# GD32H77x_78x register map
File version: 1.0
CPU: CM7 r1p2, little endian, MPU, FPU, 4 interrupt priority bits
Registers are 32-bit, read-write, reset 0x0 unless marked. A register's access mark holds for its fields unless they carry their own. Offsets are from the block's base; [hi:lo] are bit positions; {n}, {i} and the like mark numbered series.

## RSPDIF — Receiver of Sony/Philips Digtial Interface
Base 0x40004000
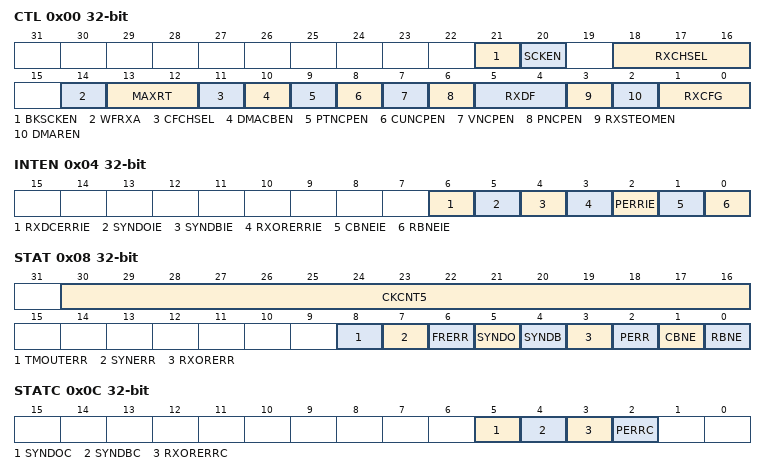
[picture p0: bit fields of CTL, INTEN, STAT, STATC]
0x00 CTL — Control register
  [21] BKSCKEN — Backup symbol clock enable
  [20] SCKEN — Symbol clock enable
  [18:16] RXCHSEL — RSPDIF input channel selection
  [14] WFRXA — Wait for the four valid transition signal of the selected RSPDIF channel
  [13:12] MAXRT — Maximum number of retries allowed during the RSPDIF synchronization phase 00: Do not allow retry (only one chance)
  [11] CFCHSEL — The control flow acquires channel state source selection
  [10] DMACBEN — Control buffer DMA enable for control flow
  [9] PTNCPEN — Preamble type no copy enable bit
  [8] CUNCPEN — Channel status and user no copy enable bit
  [7] VNCPEN — Validity no copy enable bit
  [6] PNCPEN — Parity error no copy enable bit
  [5:4] RXDF — RX data format selection
  [3] RXSTEOMEN — RX stereo mode enable
  [2] DMAREN — Receiver DMA enable for data flow
  [1:0] RXCFG — RSPDIF configuration
0x04 INTEN — Interrupt enable register
  [6] RXDCERRIE — RSPDIF data decoding error interrupt enable
  [5] SYNDOIE — Synchronization done interrupt enable
  [4] SYNDBIE — Synchronization block detected interrupt enable
  [3] RXORERRIE — RX overrun error interrupt enable
  [2] PERRIE — Parity error interrupt enable
  [1] CBNEIE — RX control buffer is no empty interrupt enable
  [0] RBNEIE — RX buffer is no empty interrupt enable
0x08 STAT ro — Status register
  [30:16] CKCNT5 — The number of consecutive time clock cycles of 5 symbols counted using ck
  [8] TMOUTERR — Time out error
  [7] SYNERR — Synchronization error
  [6] FRERR — Frame error
  [5] SYNDO — Synchronization done
  [4] SYNDB — Synchronization block detected
  [3] RXORERR — RX overrun error
  [2] PERR — Parity error
  [1] CBNE — The control buffer register is not empty
  [0] RBNE — RX data register not empty
0x0C STATC wo — Status flag clear register
  [5] SYNDOC — clears the synchronization done flag
  [4] SYNDBC — clears the synchronization block detected flag
  [3] RXORERRC — clears the RX overrun error flag
  [2] PERRC — clears the parity error flag
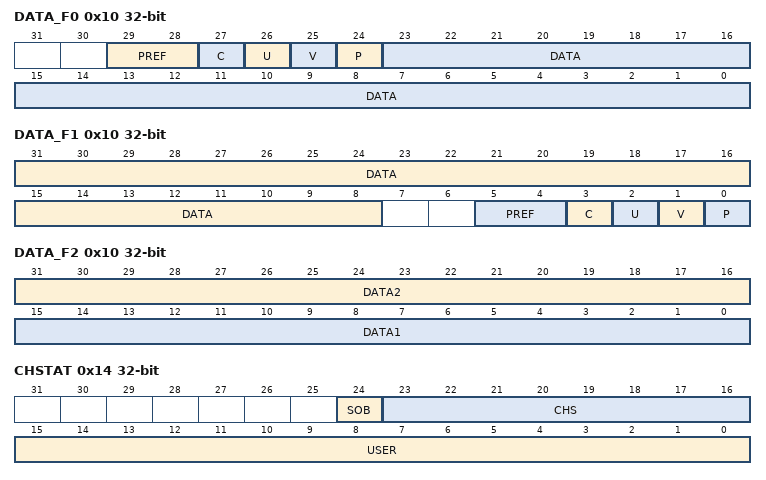
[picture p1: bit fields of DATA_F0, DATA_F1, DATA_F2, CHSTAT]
0x10 DATA_F0 ro — RX data register format 0
  [29:28] PREF — Preamble type
  [27] C — Channel status bit
  [26] U — User bit
  [25] V — Validity bit
  [24] P — Parity error bit
  [23:0] DATA — Data value
0x10 DATA_F1 ro (alternate view of DATA_F0) — RX data register format 1
  [31:8] DATA — Data value
  [5:4] PREF — Preamble type
  [3] C — Channel status bit
  [2] U — User bit
  [1] V — Validity bit
  [0] P — Parity error bit
0x10 DATA_F2 ro (alternate view of DATA_F0) — RX data register format 2
  [31:16] DATA2 — Data value
  [15:0] DATA1 — Data value
0x14 CHSTAT ro — RX Channel status register
  [24] SOB — Start of block
  [23:16] CHS — Channel A status information
  [15:0] USER — User data information
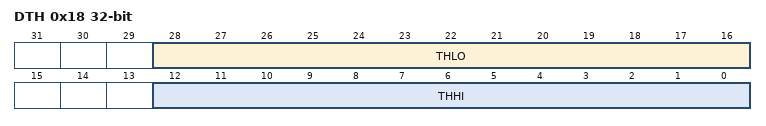
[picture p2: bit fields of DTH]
0x18 DTH ro — RX data threshold register
  [28:16] THLO — Low threshold
  [12:0] THHI — High threshold

## RTDEC0 — Real-time decryption
Base 0x5200B800
Same registers: RTDEC1 0x5200BC00
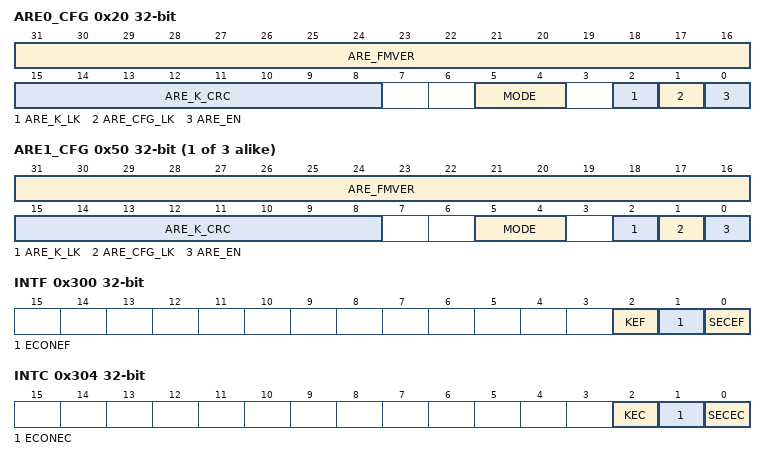
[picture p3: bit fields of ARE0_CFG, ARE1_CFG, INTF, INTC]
0x20 ARE0_CFG access per field — Area 0 configuration regist
  [31:16] ARE_FMVER rw — Area firmware version bits
  [15:8] ARE_K_CRC ro — 8-bit CRC of area key bits
  [5:4] MODE rw — RTDEC mode bits
  [2] ARE_K_LK ro — Area key lock bit
  [1] ARE_CFG_LK ro — Area configure lock bit
  [0] ARE_EN rw — Area real-time decryption enable bit
{0x24+0x30*i} ARE{i}_SADDR (i=0..3) — Area {i} start address regist
  [31:0] ARE_SADDR — Area x start address bits
{0x28+0x30*i} ARE{i}_EADDR reset 0xFFFF (i=0..3) — Area {i} end address regist
  [31:0] ARE_EADDR — Area x end address bits
0x2C ARE0_NONCE0 — Area 0 nonce 0 register 0
  [31:0] ARE_NONCE0 — Area 0 nonce address bits
0x30 ARE0_NONCE1 — Area 0 nonce register 1
  [31:0] ARE_NONCE1 — Area 0 nonce 1 address bits
{0x34+0x30*i} ARE{i}_KEY0 wo (i=0..3) — Area {i} key register
  [31:0] ARE_KEY0 — Area x key bits, ARE_KEY[31:0]
{0x38+0x30*i} ARE{i}_KEY1 wo (i=0..3) — Area {i} key register
  [31:0] ARE_KEY1 — Area x key bits, ARE_KEY[63:32]
{0x3C+0x30*i} ARE{i}_KEY2 wo (i=0..3) — Area {i} key register
  [31:0] ARE_KEY2 — Area x key bits, ARE_KEY[95:64]
{0x40+0x30*i} ARE{i}_KEY3 ro (i=0..3) — Area {i} key register
  [31:0] ARE_KEY3 — Area x key bits, ARE_KEY[127:96]
{0x20+0x30*i} ARE{i}_CFG access per field (i=1..3) — Area {i} configuration regist
  [31:16] ARE_FMVER rw — Area firmware version bits
  [15:8] ARE_K_CRC rw — 8-bit CRC of area key bits
  [5:4] MODE rw — RTDEC mode bits
  [2] ARE_K_LK ro — Area key lock bit
  [1] ARE_CFG_LK ro — Area configure lock bit
  [0] ARE_EN rw — Area real-time decryption enable bit
{0x2C+0x30*i} ARE{i}_NONCE0 (i=1..3) — Area {i} nonce register 0
  [31:0] ARE_NONCE0 — Area {i} nonce 0 address bits
0x60 ARE1_NONCE1 — Area 1 nonce register 1
  [31:0] ARE_NONCE1 — Area 1 nonce 1 address bits, ARE_RANDNUM[63:32]
0x90 ARE2_NONCE1 — Area 2 nonce register 1
  [31:0] ARE_NONCE1 — Area 2 nonce 1 address bits, ARE_RANDNUM[63:32]
0xC0 ARE3_NONCE1 — Area 3 nonce register
  [31:0] ARE_NONCE1 — Area 3 nonce 1 address bits, ARE_RANDNUM[63:32]
0x300 INTF ro — Interrupt flag register
  [2] KEF — Key error interrupt flag
  [1] ECONEF — Execute-only or execute-never error interrupt flag
  [0] SECEF — Security error interrupt flag
0x304 INTC wo — Interrupt flag clear register
  [2] KEC — Key error flag clear
  [1] ECONEC — Execute-only or execute-never error flag clear
  [0] SECEC — Security error interrupt flag
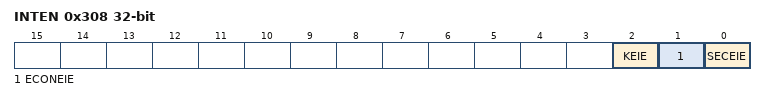
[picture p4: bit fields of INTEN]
0x308 INTEN — Interrupt enable register
  [2] KEIE — Enable bit for key error interrupt
  [1] ECONEIE — Enable bit for execute-only or execute-never error interrupt
  [0] SECEIE — Enable bit for security error interrupt
